VERSION ""

NS_ :

BS_:
BU_: currentsense
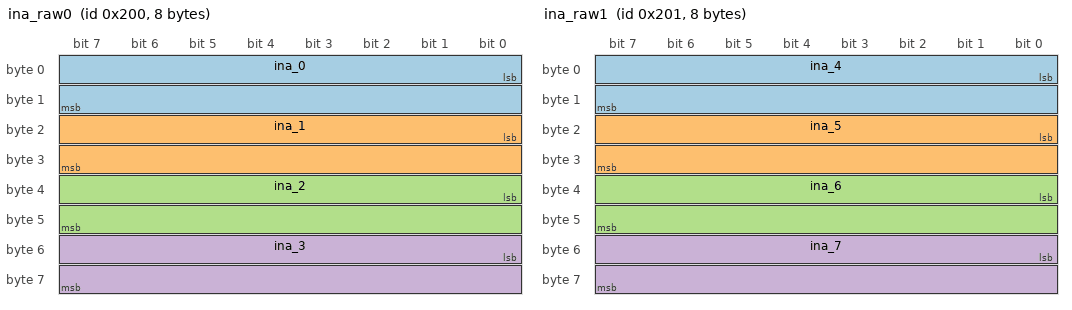
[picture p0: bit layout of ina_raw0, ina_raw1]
BO_ 512 ina_raw0: 8 currentsense
   SG_ ina_0 : 0|16@1+ (1,0) [0|4095] "" Vector__XXX
   SG_ ina_1 : 16|16@1+ (1,0) [0|4095] "" currentsense
   SG_ ina_2 : 32|16@1+ (1,0) [0|4095] "" currentsense
   SG_ ina_3 : 48|16@1+ (1,0) [0|4095] "" currentsense

BO_ 513 ina_raw1: 8 currentsense
   SG_ ina_4 : 0|16@1+ (1,0) [0|4095] "" currentsense
   SG_ ina_5 : 16|16@1+ (1,0) [0|4095] "" currentsense
   SG_ ina_6 : 32|16@1+ (1,0) [0|4095] "" currentsense
   SG_ ina_7 : 48|16@1+ (1,0) [0|4095] "" currentsense

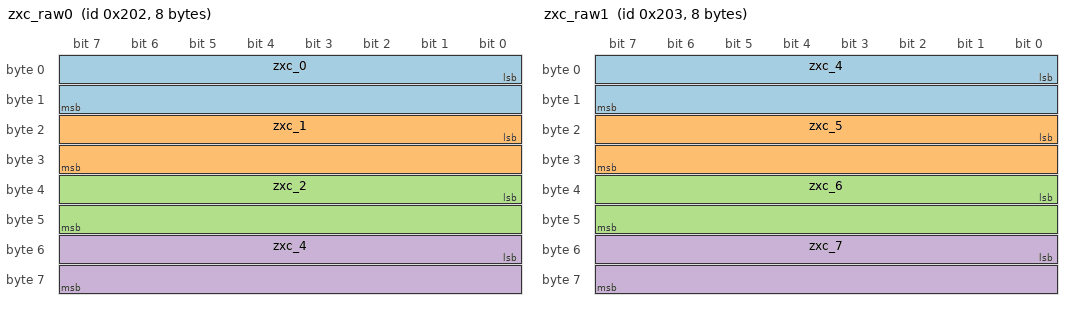
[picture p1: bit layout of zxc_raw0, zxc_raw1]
BO_ 514 zxc_raw0: 8 currentsense
   SG_ zxc_0 : 0|16@1+ (1,0) [0|4095] "" Vector__XXX
   SG_ zxc_1 : 16|16@1+ (1,0) [0|4095] "" Vector__XXX
   SG_ zxc_2 : 32|16@1+ (1,0) [0|4095] "" Vector__XXX
   SG_ zxc_4 : 48|16@1+ (1,0) [0|4095] "" Vector__XXX

BO_ 515 zxc_raw1: 8 currentsense
   SG_ zxc_4 : 0|16@1+ (1,0) [0|4095] "" Vector__XXX
   SG_ zxc_5 : 16|16@1+ (1,0) [0|4095] "" Vector__XXX
   SG_ zxc_6 : 32|16@1+ (1,0) [0|4095] "" Vector__XXX
   SG_ zxc_7 : 48|16@1+ (1,0) [0|4095] "" Vector__XXX

BA_DEF_ BO_ "GenMsgBackgroundColor" STRING ;
BA_DEF_ BO_ "GenMsgForegroundColor" STRING ;
BA_DEF_ BO_ "filterlabeling" INT 0 0;
BA_DEF_ BO_ "filterlabeling" INT 0 0;
BA_ "GenMsgForegroundColor" BO_ 512 "#00aa00";
BA_ "GenMsgForegroundColor" BO_ 514 "#000000";
BA_DEF_DEF_ "GenMsgBackgroundColor" "#ffffff";
BA_DEF_DEF_ "GenMsgForegroundColor" "#232629";
BA_DEF_DEF_ "filterlabeling" 1;
BA_DEF_DEF_ "filterlabeling" true;
CM_ BU_ currentsense "Default node if none specified";
